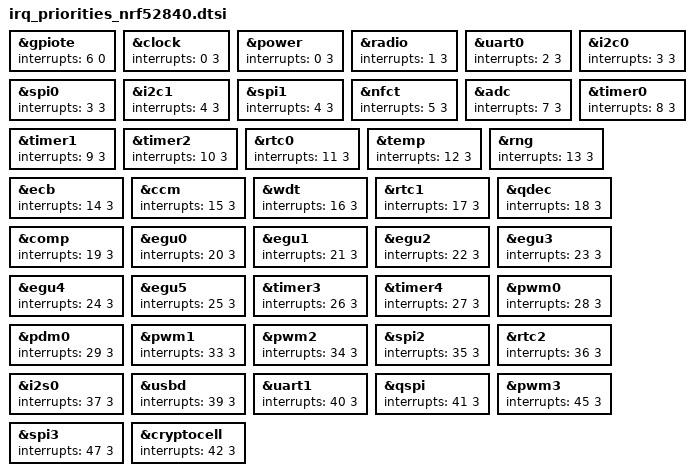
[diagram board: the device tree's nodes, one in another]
/*
 * Interrupt priorities for nRF52840 (nice!nano v2 etc.), copied unchanged from
 * the original shield: GPIOTE gets priority 0, every other peripheral gets 3.
 *
 * Define TRACKPOINT_NO_IRQ_PRIORITIES before including <trackpoint/ps2.dtsi>
 * to skip this file on other SoCs.
 */

&gpiote {
    interrupts = < 6 0 >;
};


&clock {
    interrupts = < 0 3 >;
};

&power {
    interrupts = < 0 3 >;
};

&radio {
    interrupts = < 1 3 >;
};

&uart0 {
    interrupts = < 2 3 >;
};

&i2c0 {
    interrupts = < 3 3 >;
};

&spi0 {
    interrupts = < 3 3 >;
};

&i2c1 {
    interrupts = < 4 3 >;
};

&spi1 {
    interrupts = < 4 3 >;
};

&nfct {
    interrupts = < 5 3 >;
};

&adc {
    interrupts = < 7 3 >;
};

&timer0 {
    interrupts = < 8 3 >;
};

&timer1 {
    interrupts = < 9 3 >;
};

&timer2 {
    interrupts = < 10 3 >;
};

&rtc0 {
    interrupts = < 11 3 >;
};

&temp {
    interrupts = < 12 3 >;
};

&rng {
    interrupts = < 13 3 >;
};

&ecb {
    interrupts = < 14 3 >;
};

&ccm {
    interrupts = < 15 3 >;
};

&wdt {
    interrupts = < 16 3 >;
};

&rtc1 {
    interrupts = < 17 3 >;
};

&qdec {
    interrupts = < 18 3 >;
};

&comp {
    interrupts = < 19 3 >;
};

&egu0 {
    interrupts = < 20 3 >;
};

&egu1 {
    interrupts = < 21 3 >;
};

&egu2 {
    interrupts = < 22 3 >;
};

&egu3 {
    interrupts = < 23 3 >;
};

&egu4 {
    interrupts = < 24 3 >;
};

&egu5 {
    interrupts = < 25 3 >;
};

&timer3 {
    interrupts = < 26 3 >;
};

&timer4 {
    interrupts = < 27 3 >;
};

&pwm0 {
    interrupts = < 28 3 >;
};

&pdm0 {
    interrupts = < 29 3 >;
};

&pwm1 {
    interrupts = < 33 3 >;
};

&pwm2 {
    interrupts = < 34 3 >;
};

&spi2 {
    interrupts = < 35 3 >;
};

&rtc2 {
    interrupts = < 36 3 >;
};

&i2s0 {
    interrupts = < 37 3 >;
};

&usbd {
    interrupts = < 39 3 >;
};

&uart1 {
    interrupts = < 40 3 >;
};

&qspi {
    interrupts = < 41 3 >;
};

&pwm3 {
    interrupts = < 45 3 >;
};

&spi3 {
    interrupts = < 47 3 >;
};

&cryptocell {
    interrupts = < 42 3 >;
};
